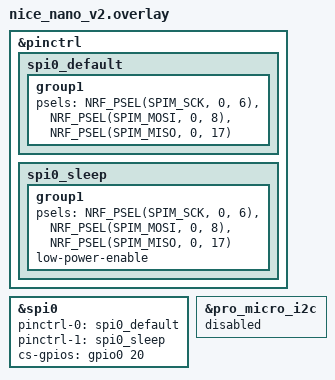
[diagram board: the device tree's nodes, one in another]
/* Copyright (c) 2021-2022 The ZMK Contributors
 * SPDX-License-Identifier: MIT
 * SCK  -> P0.06  # Connect to SCK on Nice View
 * MOSI -> P0.08  # Connect to MOSI on Nice View
 * CS   -> P0.20  # Connect to CS on Nice View
 * MISO -> P0.17  # Not physically connected (display does not use MISO)
 */

&pinctrl {
    spi0_default: spi0_default {
        group1 {
            psels = <NRF_PSEL(SPIM_SCK, 0, 6)>,
                    <NRF_PSEL(SPIM_MOSI, 0, 8)>,
                    <NRF_PSEL(SPIM_MISO, 0, 17)>;
        };
    };
    spi0_sleep: spi0_sleep {
        group1 {
            psels = <NRF_PSEL(SPIM_SCK, 0, 6)>,
                    <NRF_PSEL(SPIM_MOSI, 0, 8)>,
                    <NRF_PSEL(SPIM_MISO, 0, 17)>;
            low-power-enable;
        };
    };
};

nice_view_spi: &spi0 {
    pinctrl-0 = <&spi0_default>;
    pinctrl-1 = <&spi0_sleep>;
    pinctrl-names = "default", "sleep";
    cs-gpios = <&gpio0 20 GPIO_ACTIVE_HIGH>;
};

&pro_micro_i2c {
    status = "disabled";
};
